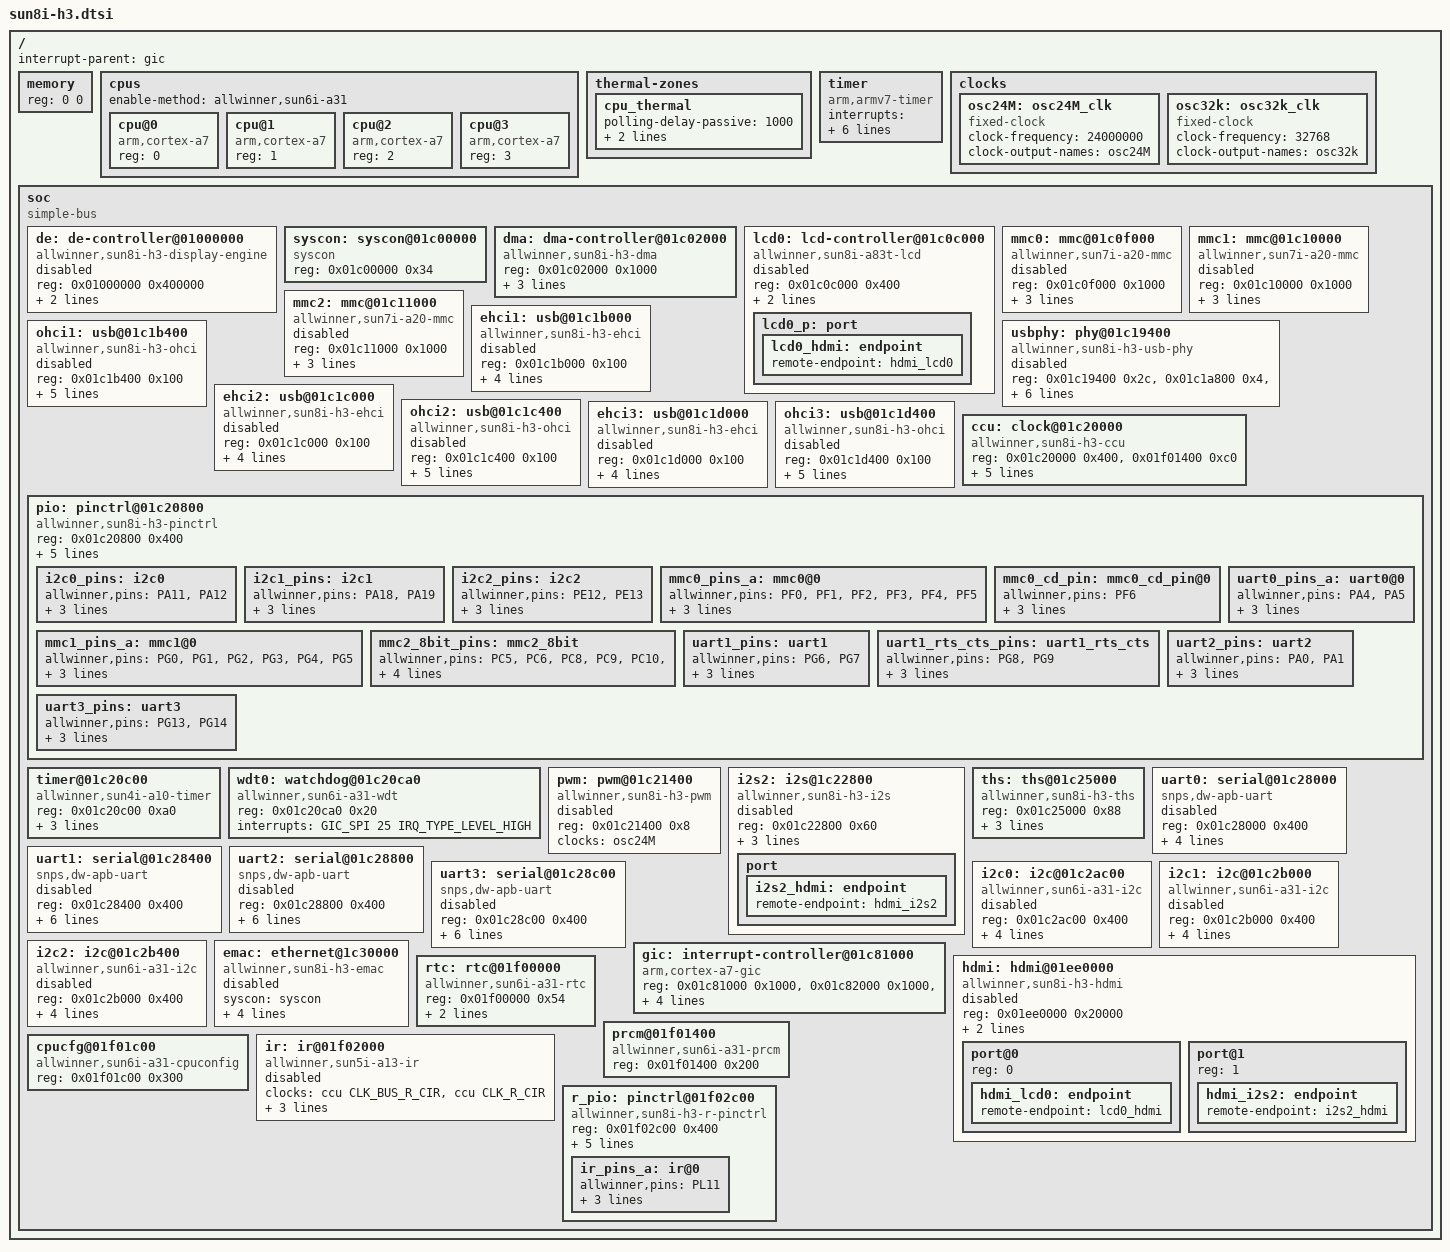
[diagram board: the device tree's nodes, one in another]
/*
 * Copyright (C) 2015 Jens Kuske <jenskuske@gmail.com>
 *
 * This file is dual-licensed: you can use it either under the terms
 * of the GPL or the X11 license, at your option. Note that this dual
 * licensing only applies to this file, and not this project as a
 * whole.
 *
 *  a) This file is free software; you can redistribute it and/or
 *     modify it under the terms of the GNU General Public License as
 *     published by the Free Software Foundation; either version 2 of the
 *     License, or (at your option) any later version.
 *
 *     This file is distributed in the hope that it will be useful,
 *     but WITHOUT ANY WARRANTY; without even the implied warranty of
 *     MERCHANTABILITY or FITNESS FOR A PARTICULAR PURPOSE.  See the
 *     GNU General Public License for more details.
 *
 * Or, alternatively,
 *
 *  b) Permission is hereby granted, free of charge, to any person
 *     obtaining a copy of this software and associated documentation
 *     files (the "Software"), to deal in the Software without
 *     restriction, including without limitation the rights to use,
 *     copy, modify, merge, publish, distribute, sublicense, and/or
 *     sell copies of the Software, and to permit persons to whom the
 *     Software is furnished to do so, subject to the following
 *     conditions:
 *
 *     The above copyright notice and this permission notice shall be
 *     included in all copies or substantial portions of the Software.
 *
 *     THE SOFTWARE IS PROVIDED "AS IS", WITHOUT WARRANTY OF ANY KIND,
 *     EXPRESS OR IMPLIED, INCLUDING BUT NOT LIMITED TO THE WARRANTIES
 *     OF MERCHANTABILITY, FITNESS FOR A PARTICULAR PURPOSE AND
 *     NONINFRINGEMENT. IN NO EVENT SHALL THE AUTHORS OR COPYRIGHT
 *     HOLDERS BE LIABLE FOR ANY CLAIM, DAMAGES OR OTHER LIABILITY,
 *     WHETHER IN AN ACTION OF CONTRACT, TORT OR OTHERWISE, ARISING
 *     FROM, OUT OF OR IN CONNECTION WITH THE SOFTWARE OR THE USE OR
 *     OTHER DEALINGS IN THE SOFTWARE.
 */

#include <dt-bindings/clock/sun8i-h3.h>
#include <dt-bindings/interrupt-controller/arm-gic.h>
#include <dt-bindings/pinctrl/sun4i-a10.h>
#include <dt-bindings/reset/sun8i-h3.h>

/ {
	interrupt-parent = <&gic>;

	#address-cells = <1>;
	#size-cells = <1>;
	memory { device_type = "memory"; reg = <0 0>; };

	cpus {
		#address-cells = <1>;
		#size-cells = <0>;

		enable-method = "allwinner,sun6i-a31";

		cpu@0 {
			compatible = "arm,cortex-a7";
			device_type = "cpu";
			reg = <0>;
//psci
//			enable-method = "psci";
//			clocks = <&ccu CLK_PLL_CPUX>;
//			clock-latency = <??>;
		};

		cpu@1 {
			compatible = "arm,cortex-a7";
			device_type = "cpu";
			reg = <1>;
//psci
//			enable-method = "psci";
		};

		cpu@2 {
			compatible = "arm,cortex-a7";
			device_type = "cpu";
			reg = <2>;
//psci
//			enable-method = "psci";
		};

		cpu@3 {
			compatible = "arm,cortex-a7";
			device_type = "cpu";
			reg = <3>;
//psci
//			enable-method = "psci";
		};
	};

//psci
//	psci {
//		compatible = "arm,psci-0.2";
//		method = "smc";
//	};

	thermal-zones {
		cpu_thermal: cpu_thermal {
			polling-delay-passive = <1000>;
			polling-delay = <5000>;
			thermal-sensors = <&ths 0>;
		};
	};

	timer {
		compatible = "arm,armv7-timer";
		interrupts = <GIC_PPI 13 (GIC_CPU_MASK_SIMPLE(4) | IRQ_TYPE_LEVEL_LOW)>,
			     <GIC_PPI 14 (GIC_CPU_MASK_SIMPLE(4) | IRQ_TYPE_LEVEL_LOW)>,
			     <GIC_PPI 11 (GIC_CPU_MASK_SIMPLE(4) | IRQ_TYPE_LEVEL_LOW)>,
			     <GIC_PPI 10 (GIC_CPU_MASK_SIMPLE(4) | IRQ_TYPE_LEVEL_LOW)>;
// from hdg and jens - needed in all cases
		clock-frequency = <24000000>;
		arm,cpu-registers-not-fw-configured;
	};

	clocks {
		#address-cells = <1>;
		#size-cells = <1>;
		ranges;

		osc24M: osc24M_clk {
			#clock-cells = <0>;
			compatible = "fixed-clock";
			clock-frequency = <24000000>;
			clock-output-names = "osc24M";
		};

		osc32k: osc32k_clk {
			#clock-cells = <0>;
			compatible = "fixed-clock";
			clock-frequency = <32768>;
			clock-output-names = "osc32k";
		};
	};

	soc {
		compatible = "simple-bus";
		#address-cells = <1>;
		#size-cells = <1>;
		ranges;

		de: de-controller@01000000 {
			compatible = "allwinner,sun8i-h3-display-engine";
			reg = <0x01000000 0x400000>;
			clocks = <&ccu CLK_DE>;
			clock-names = "clock";
//			resets = <&ccu RST_BUS_DE>;
//fixme: tv to be added
//			ports = <&lcd0_p>, <&lcd1_p>;
			ports = <&lcd0_p>;
			status = "disabled";
		};

		syscon: syscon@01c00000 {
//fixme: which compatible
			compatible = "syscon";
//fixme: size 0x1000 ?
			reg = <0x01c00000 0x34>;
		};

		dma: dma-controller@01c02000 {
			compatible = "allwinner,sun8i-h3-dma";
			reg = <0x01c02000 0x1000>;
			interrupts = <GIC_SPI 50 IRQ_TYPE_LEVEL_HIGH>;
#if 0 // needed if no uart0
			clocks = <&osc24M>;
#else
			clocks = <&ccu CLK_BUS_DMA>;
			resets = <&ccu RST_BUS_DMA>;
#endif
			#dma-cells = <1>;
		};

		lcd0: lcd-controller@01c0c000 {
			compatible = "allwinner,sun8i-a83t-lcd";
			reg = <0x01c0c000 0x400>;
			clocks = <&ccu CLK_TCON0>;
			clock-names = "clock";
			interrupts = <GIC_SPI 86 IRQ_TYPE_LEVEL_HIGH>;
			status = "disabled";
			#address-cells = <1>;
			#size-cells = <0>;
			lcd0_p: port {
				lcd0_hdmi: endpoint {
					remote-endpoint = <&hdmi_lcd0>;
				};
			};
		};

//		lcd1: lcd-controller@01c0d000 {
//			compatible = "allwinner,sun8i-h3-lcd";
//			reg = <0x01c0d000 0x400>;
//			clocks = <&ccu CLK_BUS_TCON1>, <&ccu ???>;
//			clock-names = "gate", "clock";
//			interrupts = <GIC_SPI 87 IRQ_TYPE_LEVEL_HIGH>;
//			status = "disabled";
//			#address-cells = <1>;
//			#size-cells = <0>;
//			lcd1_p: port {
//				lcd1_tve: endpoint {
//					remote-endpoint = <&tve_lcd1>;
//				};
//			};
//		};

		mmc0: mmc@01c0f000 {
			compatible = "allwinner,sun7i-a20-mmc";
			reg = <0x01c0f000 0x1000>;
			clocks = <&ccu CLK_BUS_MMC0>,
				 <&ccu CLK_MMC0>,
				 <&ccu CLK_MMC0_OUTPUT>,
				 <&ccu CLK_MMC0_SAMPLE>;
			clock-names = "ahb",
				      "mmc",
				      "output",
				      "sample";
//			resets = <&ccu RST_BUS_MMC0>;
//			reset-names = "ahb";
			interrupts = <GIC_SPI 60 IRQ_TYPE_LEVEL_HIGH>;
			status = "disabled";
			#address-cells = <1>;
			#size-cells = <0>;
		};

		mmc1: mmc@01c10000 {
			compatible = "allwinner,sun7i-a20-mmc";
			reg = <0x01c10000 0x1000>;
			clocks = <&ccu CLK_BUS_MMC1>,
				 <&ccu CLK_MMC1>,
				 <&ccu CLK_MMC1_OUTPUT>,
				 <&ccu CLK_MMC1_SAMPLE>;
			clock-names = "ahb",
				      "mmc",
				      "output",
				      "sample";
//			resets = <&ccu RST_BUS_MMC1>;
//			reset-names = "ahb";
			interrupts = <GIC_SPI 61 IRQ_TYPE_LEVEL_HIGH>;
			status = "disabled";
			#address-cells = <1>;
			#size-cells = <0>;
		};

		mmc2: mmc@01c11000 {
			compatible = "allwinner,sun7i-a20-mmc";
			reg = <0x01c11000 0x1000>;
			clocks = <&ccu CLK_BUS_MMC2>,
				 <&ccu CLK_MMC2>,
				 <&ccu CLK_MMC2_OUTPUT>,
				 <&ccu CLK_MMC2_SAMPLE>;
			clock-names = "ahb",
				      "mmc",
				      "output",
				      "sample";
//			resets = <&ccu RST_BUS_MMC2>;
//			reset-names = "ahb";
			interrupts = <GIC_SPI 62 IRQ_TYPE_LEVEL_HIGH>;
			status = "disabled";
			#address-cells = <1>;
			#size-cells = <0>;
		};

#if 0 // useless
		sid: eeprom@01c14000 {
			compatible = "allwinner,sun4i-a10-sid";
			reg = <0x01c14000 0x400>;
			#address-cells = <1>;
			#size-cells = <1>;

//useless if not android
//			ths_calibration: calib@234 {
//				reg = <0x234 0x4>;
//			};
		};
#endif

		usbphy: phy@01c19400 {
			compatible = "allwinner,sun8i-h3-usb-phy";
			reg = <0x01c19400 0x2c>,
			      <0x01c1a800 0x4>,
			      <0x01c1b800 0x4>,
			      <0x01c1c800 0x4>,
			      <0x01c1d800 0x4>;
			reg-names = "phy_ctrl",
				    "pmu0",
				    "pmu1",
				    "pmu2",
				    "pmu3";
			clocks = <&ccu CLK_USB_PHY0>,
				 <&ccu CLK_USB_PHY1>,
				 <&ccu CLK_USB_PHY2>,
				 <&ccu CLK_USB_PHY3>;
			clock-names = "usb0_phy",
				      "usb1_phy",
				      "usb2_phy",
				      "usb3_phy";
			resets = <&ccu RST_USB_PHY0>,
				 <&ccu RST_USB_PHY1>,
				 <&ccu RST_USB_PHY2>,
				 <&ccu RST_USB_PHY3>;
			reset-names = "usb0_reset",
				      "usb1_reset",
				      "usb2_reset",
				      "usb3_reset";
			status = "disabled";
			#phy-cells = <1>;
		};

		ehci1: usb@01c1b000 {
			compatible = "allwinner,sun8i-h3-ehci", "generic-ehci";
			reg = <0x01c1b000 0x100>;
			interrupts = <GIC_SPI 74 IRQ_TYPE_LEVEL_HIGH>;
			clocks = <&ccu CLK_BUS_EHCI1>, <&ccu CLK_BUS_OHCI1>;
			resets = <&ccu RST_BUS_EHCI1>, <&ccu RST_BUS_OHCI1>;
			phys = <&usbphy 1>;
			phy-names = "usb";
			status = "disabled";
		};

		ohci1: usb@01c1b400 {
			compatible = "allwinner,sun8i-h3-ohci", "generic-ohci";
			reg = <0x01c1b400 0x100>;
			interrupts = <GIC_SPI 75 IRQ_TYPE_LEVEL_HIGH>;
			clocks = <&ccu CLK_BUS_EHCI1>, <&ccu CLK_BUS_OHCI1>,
				 <&ccu CLK_USB_OHCI1>;
			resets = <&ccu RST_BUS_EHCI1>, <&ccu RST_BUS_OHCI1>;
			phys = <&usbphy 1>;
			phy-names = "usb";
			status = "disabled";
		};

		ehci2: usb@01c1c000 {
			compatible = "allwinner,sun8i-h3-ehci", "generic-ehci";
			reg = <0x01c1c000 0x100>;
			interrupts = <GIC_SPI 76 IRQ_TYPE_LEVEL_HIGH>;
			clocks = <&ccu CLK_BUS_EHCI2>, <&ccu CLK_BUS_OHCI2>;
			resets = <&ccu RST_BUS_EHCI2>, <&ccu RST_BUS_OHCI2>;
			phys = <&usbphy 2>;
			phy-names = "usb";
			status = "disabled";
		};

		ohci2: usb@01c1c400 {
			compatible = "allwinner,sun8i-h3-ohci", "generic-ohci";
			reg = <0x01c1c400 0x100>;
			interrupts = <GIC_SPI 77 IRQ_TYPE_LEVEL_HIGH>;
			clocks = <&ccu CLK_BUS_EHCI2>, <&ccu CLK_BUS_OHCI2>,
				 <&ccu CLK_USB_OHCI2>;
			resets = <&ccu RST_BUS_EHCI2>, <&ccu RST_BUS_OHCI2>;
			phys = <&usbphy 2>;
			phy-names = "usb";
			status = "disabled";
		};

		ehci3: usb@01c1d000 {
			compatible = "allwinner,sun8i-h3-ehci", "generic-ehci";
			reg = <0x01c1d000 0x100>;
			interrupts = <GIC_SPI 78 IRQ_TYPE_LEVEL_HIGH>;
			clocks = <&ccu CLK_BUS_EHCI3>, <&ccu CLK_BUS_OHCI3>;
			resets = <&ccu RST_BUS_EHCI3>, <&ccu RST_BUS_OHCI3>;
			phys = <&usbphy 3>;
			phy-names = "usb";
			status = "disabled";
		};

		ohci3: usb@01c1d400 {
			compatible = "allwinner,sun8i-h3-ohci", "generic-ohci";
			reg = <0x01c1d400 0x100>;
			interrupts = <GIC_SPI 79 IRQ_TYPE_LEVEL_HIGH>;
			clocks = <&ccu CLK_BUS_EHCI3>, <&ccu CLK_BUS_OHCI3>,
				 <&ccu CLK_USB_OHCI3>;
			resets = <&ccu RST_BUS_EHCI3>, <&ccu RST_BUS_OHCI3>;
			phys = <&usbphy 3>;
			phy-names = "usb";
			status = "disabled";
		};

		ccu: clock@01c20000 {
			compatible = "allwinner,sun8i-h3-ccu";
			reg =	<0x01c20000 0x400>,	/* CCU */
				<0x01f01400 0xc0>;	/* PRCM */
			clocks = <&osc24M>, <&osc32k>;
			clock-names = "hosc", "losc";
			#clock-cells = <1>;
			#reset-cells = <1>;

			assigned-clocks = <&ccu CLK_PLL_PERIPH0>,
					  <&ccu CLK_PLL_PERIPH1>,
//					  <&ccu CLK_PLL_DE>,
					  <&ccu CLK_DE>;
			assigned-clock-rates =  <600000000>,
						<600000000>,
//						<864000000>,
						<432000000>;
		};

		pio: pinctrl@01c20800 {
			compatible = "allwinner,sun8i-h3-pinctrl";
			reg = <0x01c20800 0x400>;
			interrupts = <GIC_SPI 11 IRQ_TYPE_LEVEL_HIGH>,
				     <GIC_SPI 17 IRQ_TYPE_LEVEL_HIGH>;
#if 1 // needed if no uart0
			clocks = <&osc24M>;
#else
			clocks = <&ccu CLK_BUS_PIO>;
#endif
			gpio-controller;
			#gpio-cells = <3>;
			interrupt-controller;
			#interrupt-cells = <3>;

			i2c0_pins: i2c0 {
				allwinner,pins = "PA11", "PA12";
				allwinner,function = "i2c0";
				allwinner,drive = <SUN4I_PINCTRL_10_MA>;
				allwinner,pull = <SUN4I_PINCTRL_NO_PULL>;
			};

			i2c1_pins: i2c1 {
				allwinner,pins = "PA18", "PA19";
				allwinner,function = "i2c1";
				allwinner,drive = <SUN4I_PINCTRL_10_MA>;
				allwinner,pull = <SUN4I_PINCTRL_NO_PULL>;
			};

			i2c2_pins: i2c2 {
				allwinner,pins = "PE12", "PE13";
				allwinner,function = "i2c2";
				allwinner,drive = <SUN4I_PINCTRL_10_MA>;
				allwinner,pull = <SUN4I_PINCTRL_NO_PULL>;
			};

			mmc0_pins_a: mmc0@0 {
				allwinner,pins = "PF0", "PF1", "PF2", "PF3",
						 "PF4", "PF5";
				allwinner,function = "mmc0";
				allwinner,drive = <SUN4I_PINCTRL_30_MA>;
				allwinner,pull = <SUN4I_PINCTRL_NO_PULL>;
			};

			mmc0_cd_pin: mmc0_cd_pin@0 {
				allwinner,pins = "PF6";
				allwinner,function = "gpio_in";
				allwinner,drive = <SUN4I_PINCTRL_10_MA>;
				allwinner,pull = <SUN4I_PINCTRL_PULL_UP>;
			};

			mmc1_pins_a: mmc1@0 {
				allwinner,pins = "PG0", "PG1", "PG2", "PG3",
						 "PG4", "PG5";
				allwinner,function = "mmc1";
				allwinner,drive = <SUN4I_PINCTRL_30_MA>;
				allwinner,pull = <SUN4I_PINCTRL_NO_PULL>;
			};

			mmc2_8bit_pins: mmc2_8bit {
				allwinner,pins = "PC5", "PC6", "PC8",
						 "PC9", "PC10", "PC11",
						 "PC12", "PC13", "PC14",
						 "PC15", "PC16";
				allwinner,function = "mmc2";
				allwinner,drive = <SUN4I_PINCTRL_30_MA>;
				allwinner,pull = <SUN4I_PINCTRL_NO_PULL>;
			};

			uart0_pins_a: uart0@0 {
				allwinner,pins = "PA4", "PA5";
				allwinner,function = "uart0";
				allwinner,drive = <SUN4I_PINCTRL_10_MA>;
				allwinner,pull = <SUN4I_PINCTRL_NO_PULL>;
			};

			uart1_pins: uart1 {
				allwinner,pins = "PG6", "PG7";
				allwinner,function = "uart1";
				allwinner,drive = <SUN4I_PINCTRL_10_MA>;
				allwinner,pull = <SUN4I_PINCTRL_NO_PULL>;
			};

			uart1_rts_cts_pins: uart1_rts_cts {
				allwinner,pins = "PG8", "PG9";
				allwinner,function = "uart1";
				allwinner,drive = <SUN4I_PINCTRL_10_MA>;
				allwinner,pull = <SUN4I_PINCTRL_NO_PULL>;
			};

			uart2_pins: uart2 {
				allwinner,pins = "PA0", "PA1";
				allwinner,function = "uart2";
				allwinner,drive = <SUN4I_PINCTRL_10_MA>;
				allwinner,pull = <SUN4I_PINCTRL_NO_PULL>;
			};

			uart3_pins: uart3 {
				allwinner,pins = "PG13", "PG14";
				allwinner,function = "uart3";
				allwinner,drive = <SUN4I_PINCTRL_10_MA>;
				allwinner,pull = <SUN4I_PINCTRL_NO_PULL>;
			};
		};

		timer@01c20c00 {
			compatible = "allwinner,sun4i-a10-timer";
			reg = <0x01c20c00 0xa0>;
			interrupts = <GIC_SPI 18 IRQ_TYPE_LEVEL_HIGH>,
				     <GIC_SPI 19 IRQ_TYPE_LEVEL_HIGH>;
			clocks = <&osc24M>;
		};

		wdt0: watchdog@01c20ca0 {
			compatible = "allwinner,sun6i-a31-wdt";
			reg = <0x01c20ca0 0x20>;
			interrupts = <GIC_SPI 25 IRQ_TYPE_LEVEL_HIGH>;
		};

		pwm: pwm@01c21400 {
			compatible = "allwinner,sun8i-h3-pwm";
			reg = <0x01c21400 0x8>;
			clocks = <&osc24M>;
			#pwm-cells = <3>;
			status = "disabled";
		};

		i2s2: i2s@1c22800 {
			compatible = "allwinner,sun8i-h3-i2s";
			reg = <0x01c22800 0x60>;
			clocks = <&ccu CLK_I2S2>;
			clock-names = "mod";
			resets = <&ccu RST_BUS_I2S2>;
			dmas = <&dma 27>;
			dma-names = "tx";
			status = "disabled";
			port {
				i2s2_hdmi: endpoint {
					remote-endpoint = <&hdmi_i2s2>;
				};
			};
		};

		ths: ths@01c25000 {
			#thermal-sensor-cells = <0>;
			compatible = "allwinner,sun8i-h3-ths";
			reg = <0x01c25000 0x88>;
			interrupts = <GIC_SPI 31 IRQ_TYPE_LEVEL_HIGH>;
			clocks = <&ccu CLK_THS>;
			resets = <&ccu RST_BUS_THS>;
//useless if not android
//			nvmem-cells = <&ths_calibration>;
//			nvmem-cell-names = "calibration";
		};

		uart0: serial@01c28000 {
			compatible = "snps,dw-apb-uart";
			reg = <0x01c28000 0x400>;
			interrupts = <GIC_SPI 0 IRQ_TYPE_LEVEL_HIGH>;
			reg-shift = <2>;
			reg-io-width = <4>;
#if 1 // needed if no uart0
			clocks = <&osc24M>;
#else
			clocks = <&ccu CLK_BUS_UART0>;
			resets = <&ccu RST_BUS_UART0>;
			dmas = <&dma 6>, <&dma 6>;
			dma-names = "rx", "tx";
#endif
			status = "disabled";
		};

		uart1: serial@01c28400 {
			compatible = "snps,dw-apb-uart";
			reg = <0x01c28400 0x400>;
			interrupts = <GIC_SPI 1 IRQ_TYPE_LEVEL_HIGH>;
			reg-shift = <2>;
			reg-io-width = <4>;
			clocks = <&ccu CLK_BUS_UART1>;
			resets = <&ccu RST_BUS_UART1>;
			dmas = <&dma 7>, <&dma 7>;
			dma-names = "rx", "tx";
			status = "disabled";
		};

		uart2: serial@01c28800 {
			compatible = "snps,dw-apb-uart";
			reg = <0x01c28800 0x400>;
			interrupts = <GIC_SPI 2 IRQ_TYPE_LEVEL_HIGH>;
			reg-shift = <2>;
			reg-io-width = <4>;
			clocks = <&ccu CLK_BUS_UART2>;
			resets = <&ccu RST_BUS_UART2>;
			dmas = <&dma 8>, <&dma 8>;
			dma-names = "rx", "tx";
			status = "disabled";
		};

		uart3: serial@01c28c00 {
			compatible = "snps,dw-apb-uart";
			reg = <0x01c28c00 0x400>;
			interrupts = <GIC_SPI 3 IRQ_TYPE_LEVEL_HIGH>;
			reg-shift = <2>;
			reg-io-width = <4>;
			clocks = <&ccu CLK_BUS_UART3>;
			resets = <&ccu RST_BUS_UART3>;
			dmas = <&dma 9>, <&dma 9>;
			dma-names = "rx", "tx";
			status = "disabled";
		};

		i2c0: i2c@01c2ac00 {
			compatible = "allwinner,sun6i-a31-i2c";
			reg = <0x01c2ac00 0x400>;
			interrupts = <GIC_SPI 6 IRQ_TYPE_LEVEL_HIGH>;
			clocks = <&ccu CLK_BUS_I2C0>;
			resets = <&ccu RST_BUS_I2C0>;
			pinctrl-names = "default";
			pinctrl-0 = <&i2c0_pins>;
			status = "disabled";
			#address-cells = <1>;
			#size-cells = <0>;
		};

		i2c1: i2c@01c2b000 {
			compatible = "allwinner,sun6i-a31-i2c";
			reg = <0x01c2b000 0x400>;
			interrupts = <GIC_SPI 7 IRQ_TYPE_LEVEL_HIGH>;
			clocks = <&ccu CLK_BUS_I2C1>;
			resets = <&ccu RST_BUS_I2C1>;
			pinctrl-names = "default";
			pinctrl-0 = <&i2c1_pins>;
			status = "disabled";
			#address-cells = <1>;
			#size-cells = <0>;
		};

		i2c2: i2c@01c2b400 {
			compatible = "allwinner,sun6i-a31-i2c";
			reg = <0x01c2b000 0x400>;
			interrupts = <GIC_SPI 8 IRQ_TYPE_LEVEL_HIGH>;
			clocks = <&ccu CLK_BUS_I2C2>;
			resets = <&ccu RST_BUS_I2C2>;
			pinctrl-names = "default";
			pinctrl-0 = <&i2c2_pins>;
			status = "disabled";
			#address-cells = <1>;
			#size-cells = <0>;
		};

		emac: ethernet@1c30000 {
			compatible = "allwinner,sun8i-h3-emac";
			syscon = <&syscon>;
			reg = <0x01c30000 0x104>;
			interrupts = <GIC_SPI 82 IRQ_TYPE_LEVEL_HIGH>;
			resets = <&ccu RST_BUS_EMAC>, <&ccu RST_BUS_EPHY>;
			reset-names = "ahb", "ephy";
			clocks = <&ccu CLK_BUS_EMAC>, <&ccu CLK_BUS_EPHY>;
			clock-names = "ahb", "ephy";
			#address-cells = <1>;
			#size-cells = <0>;
			status = "disabled";
		};

		gic: interrupt-controller@01c81000 {
			compatible = "arm,cortex-a7-gic", "arm,cortex-a15-gic";
			reg = <0x01c81000 0x1000>,
			      <0x01c82000 0x1000>,
			      <0x01c84000 0x2000>,
			      <0x01c86000 0x2000>;
			interrupt-controller;
			#interrupt-cells = <3>;
			interrupts = <GIC_PPI 9 (GIC_CPU_MASK_SIMPLE(4) | IRQ_TYPE_LEVEL_HIGH)>;
		};

//		tve {
//			compatible = "allwinner,sun8i-h3-tve";
//			reg = <0x01e00000 0x10000>;
//			clocks = <&ccu CLK_BUS_TVE>, <&ccu CLK_TVE>;
//			clock-names = "gate", "clock";
//			resets = <&ccu RST_BUS_TVE>;
//			status = "disabled";
//			#address-cells = <1>;
//			#size-cells = <0>;
//			port {
//				tve_lcd1: endpoint {
//					remote-endpoint = <&lcd1_tve>;
//				};
//			};
//		};

		hdmi: hdmi@01ee0000 {
			compatible = "allwinner,sun8i-h3-hdmi";
			reg = <0x01ee0000 0x20000>;
			clocks = <&ccu CLK_HDMI>, <&ccu CLK_HDMI_DDC>;
			clock-names = "clock", "ddc-clock";
			resets = <&ccu RST_BUS_HDMI0>, <&ccu RST_BUS_HDMI1>;
			reset-names = "hdmi0", "hdmi1";
			status = "disabled";
			#address-cells = <1>;
			#size-cells = <0>;
			port@0 {
				reg = <0>;
				hdmi_lcd0: endpoint {
					remote-endpoint = <&lcd0_hdmi>;
				};
			};
			port@1 {
				reg = <1>;
				hdmi_i2s2: endpoint {
					remote-endpoint = <&i2s2_hdmi>;
				};
			};
		};

		rtc: rtc@01f00000 {
			compatible = "allwinner,sun6i-a31-rtc";
			reg = <0x01f00000 0x54>;
			interrupts = <GIC_SPI 40 IRQ_TYPE_LEVEL_HIGH>,
				     <GIC_SPI 41 IRQ_TYPE_LEVEL_HIGH>;
		};

		prcm@01f01400 {
			compatible = "allwinner,sun6i-a31-prcm";
			reg = <0x01f01400 0x200>;
		};

		cpucfg@01f01c00 {
			compatible = "allwinner,sun6i-a31-cpuconfig";
			reg = <0x01f01c00 0x300>;
		};

		ir: ir@01f02000 {
			compatible = "allwinner,sun5i-a13-ir";
			clocks = <&ccu CLK_BUS_R_CIR>, <&ccu CLK_R_CIR>;
			clock-names = "apb", "ir";
			resets = <&ccu RST_R_CIR>;
			interrupts = <GIC_SPI 37 IRQ_TYPE_LEVEL_HIGH>;
			reg = <0x01f02000 0x40>;
			status = "disabled";
		};

		r_pio: pinctrl@01f02c00 {
			compatible = "allwinner,sun8i-h3-r-pinctrl";
			reg = <0x01f02c00 0x400>;
			interrupts = <GIC_SPI 45 IRQ_TYPE_LEVEL_HIGH>;
			clocks = <&ccu CLK_BUS_R_PIO>;
			resets = <&ccu RST_R_PIO>;
			gpio-controller;
			#gpio-cells = <3>;
			interrupt-controller;
			#interrupt-cells = <3>;

			ir_pins_a: ir@0 {
				allwinner,pins = "PL11";
				allwinner,function = "s_cir_rx";
				allwinner,drive = <SUN4I_PINCTRL_10_MA>;
				allwinner,pull = <SUN4I_PINCTRL_NO_PULL>;
			};
		};
	};
};
